AUTOSAR XML (schema 3-2-1)
package /Demo/DemoSWC_swc
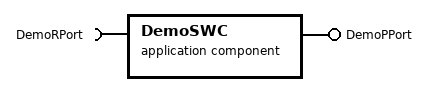
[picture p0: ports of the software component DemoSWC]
  application software component type DemoSWC
    require port DemoRPort: unqueued-receiver-com-spec{data-element=DemoDE, alive-timeout=60.0}, required_interface=DemoInterface
    provide port DemoPPort
  internal behavior DemoSWCBehavior: component=DemoSWC
  swc implementation DemoSWCImplementation: behavior=DemoSWCBehavior
